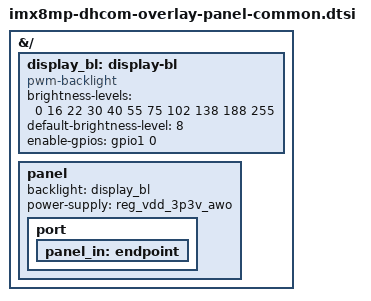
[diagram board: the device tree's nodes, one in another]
// SPDX-License-Identifier: (GPL-2.0+ OR MIT)
/*
 * Copyright (C) 2023-2026 Marek Vasut
 */

#include <dt-bindings/gpio/gpio.h>
#include <dt-bindings/input/input.h>
#include <dt-bindings/interrupt-controller/arm-gic.h>
#include <dt-bindings/pwm/pwm.h>

#include "imx8mp-dhcom-overlay-panel-clock.dtsi"

&{/} {
	display_bl: display-bl {
		compatible = "pwm-backlight";
		brightness-levels = <0 16 22 30 40 55 75 102 138 188 255>;
		default-brightness-level = <8>;
		enable-gpios = <&gpio1 0 GPIO_ACTIVE_HIGH>;	/* GPIO G */
		status = "okay";
	};

	panel: panel {
		backlight = <&display_bl>;
		power-supply = <&reg_vdd_3p3v_awo>;

		port {
			panel_in: endpoint {
			};
		};
	};
};
